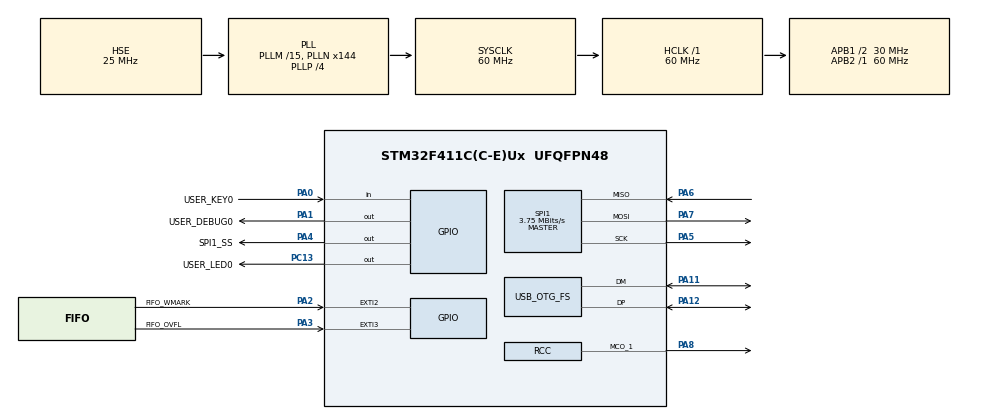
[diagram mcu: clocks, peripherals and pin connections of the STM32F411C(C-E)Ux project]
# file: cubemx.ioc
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Mcu.Family=STM32F4
Mcu.Name=STM32F411C(C-E)Ux
Mcu.Package=UFQFPN48
NVIC.EXTI2_IRQn=true\:0\:0\:false\:false\:true\:true\:true\:true
NVIC.EXTI3_IRQn=true\:0\:0\:false\:false\:true\:true\:true\:true
NVIC.OTG_FS_IRQn=true\:0\:0\:false\:false\:true\:false\:true\:true
NVIC.PriorityGroup=NVIC_PRIORITYGROUP_4
NVIC.TIM3_IRQn=true\:0\:0\:false\:false\:true\:true\:true\:true
PA0-WKUP.GPIO_Label=USER_KEY0
PA0-WKUP.Signal=GPIO_Input
PA1.GPIO_Label=USER_DEBUG0
PA1.GPIO_PuPd=GPIO_PULLDOWN
PA1.Signal=GPIO_Output
PA11.Mode=Device_Only
PA11.Signal=USB_OTG_FS_DM
PA12.Mode=Device_Only
PA12.Signal=USB_OTG_FS_DP
PA13.Mode=Serial_Wire
PA13.Signal=SYS_JTMS-SWDIO
PA14.Mode=Serial_Wire
PA14.Signal=SYS_JTCK-SWCLK
PA2.GPIO_Label=FIFO_WMARK
PA2.GPIO_ModeDefaultEXTI=GPIO_MODE_IT_RISING_FALLING
PA2.GPIO_PuPd=GPIO_PULLDOWN
PA2.Signal=GPXTI2
PA3.GPIO_Label=FIFO_OVFL
PA3.GPIO_ModeDefaultEXTI=GPIO_MODE_IT_RISING_FALLING
PA3.GPIO_PuPd=GPIO_PULLDOWN
PA3.Signal=GPXTI3
PA4.GPIO_Label=SPI1_SS
PA4.GPIO_PuPd=GPIO_NOPULL
PA4.GPIO_Speed=GPIO_SPEED_FREQ_LOW
PA4.PinState=GPIO_PIN_SET
PA4.Signal=GPIO_Output
PA5.GPIO_PuPd=GPIO_NOPULL
PA5.GPIO_Speed=GPIO_SPEED_FREQ_LOW
PA5.Mode=Full_Duplex_Master
PA5.Signal=SPI1_SCK
PA6.GPIO_PuPd=GPIO_NOPULL
PA6.GPIO_Speed=GPIO_SPEED_FREQ_LOW
PA6.Mode=Full_Duplex_Master
PA6.Signal=SPI1_MISO
PA7.GPIO_PuPd=GPIO_NOPULL
PA7.GPIO_Speed=GPIO_SPEED_FREQ_LOW
PA7.Mode=Full_Duplex_Master
PA7.Signal=SPI1_MOSI
PA8.Mode=Clock-out-1
PA8.Signal=RCC_MCO_1
PC13-ANTI_TAMP.GPIO_Label=USER_LED0
PC13-ANTI_TAMP.PinState=GPIO_PIN_SET
PC13-ANTI_TAMP.Signal=GPIO_Output
PC14-OSC32_IN.Mode=LSE-External-Oscillator
PC14-OSC32_IN.Signal=RCC_OSC32_IN
PC15-OSC32_OUT.Mode=LSE-External-Oscillator
PC15-OSC32_OUT.Signal=RCC_OSC32_OUT
PH0\ -\ OSC_IN.Mode=HSE-External-Oscillator
PH0\ -\ OSC_IN.Signal=RCC_OSC_IN
PH1\ -\ OSC_OUT.Mode=HSE-External-Oscillator
PH1\ -\ OSC_OUT.Signal=RCC_OSC_OUT
ProjectManager.HeapSize=0x200
ProjectManager.StackSize=0x400
ProjectManager.TargetToolchain=STM32CubeIDE
RCC.48MHZClocksFreq_Value=48000000
RCC.AHBFreq_Value=60000000
RCC.APB1CLKDivider=RCC_HCLK_DIV2
RCC.APB1Freq_Value=30000000
RCC.APB1TimFreq_Value=60000000
RCC.APB2Freq_Value=60000000
RCC.APB2TimFreq_Value=60000000
RCC.CortexFreq_Value=60000000
RCC.HCLKFreq_Value=60000000
RCC.HSE_VALUE=25000000
RCC.HSI_VALUE=16000000
RCC.PLLM=15
RCC.PLLN=144
RCC.PLLP=RCC_PLLP_DIV4
RCC.PLLQ=5
RCC.RCC_MCO1Source=RCC_MCO1SOURCE_PLLCLK
RCC.RCC_MCODiv1=RCC_MCODIV_5
RCC.RCC_RTC_Clock_SourceVirtual=RCC_RTCCLKSOURCE_LSE
RCC.SYSCLKFreq_VALUE=60000000
RCC.SYSCLKSource=RCC_SYSCLKSOURCE_PLLCLK
RCC.VCOOutputFreq_Value=240000000
SPI1.BaudRatePrescaler=SPI_BAUDRATEPRESCALER_16
SPI1.CLKPhase=SPI_PHASE_2EDGE
SPI1.CLKPolarity=SPI_POLARITY_HIGH
SPI1.CalculateBaudRate=3.75 MBits/s
SPI1.Direction=SPI_DIRECTION_2LINES
SPI1.FirstBit=SPI_FIRSTBIT_MSB
SPI1.Mode=SPI_MODE_MASTER
SPI1.VirtualType=VM_MASTER
TIM3.AutoReloadPreload=TIM_AUTORELOAD_PRELOAD_ENABLE
TIM3.Period=300
TIM3.Prescaler=0
USB_DEVICE.APP_RX_DATA_SIZE=2048
USB_DEVICE.CLASS_NAME_FS=CDC
USB_DEVICE.MANUFACTURER_STRING=3DP Accelerometer
USB_DEVICE.PID_CDC_FS=57626
USB_DEVICE.PRODUCT_STRING_CDC_FS=3dpaxxel
USB_DEVICE.USBD_SELF_POWERED=0
USB_DEVICE.VID=4617
USB_DEVICE.VirtualMode=Cdc
USB_DEVICE.VirtualModeFS=Cdc_FS
USB_OTG_FS.VirtualMode=Device_Only
VP_RTC_VS_RTC_Activate.Mode=RTC_Enabled
VP_TIM3_VS_ClockSourceINT.Mode=Internal
VP_USB_DEVICE_VS_USB_DEVICE_CDC_FS.Mode=CDC_FS
board=custom

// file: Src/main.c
/* USER CODE BEGIN Header */
/**
 ******************************************************************************
 * @file           : main.c
 * @brief          : Main program body
 ******************************************************************************
 * @attention
 *
 * Copyright (c) 2023 STMicroelectronics.
 * All rights reserved.
 *
 * This software is licensed under terms that can be found in the LICENSE file
 * in the root directory of this software component.
 * If no LICENSE file comes with this software, it is provided AS-IS.
 *
 ******************************************************************************
 */
/* USER CODE END Header */
#include "main.h"
#include "gpio.h"
#include "rtc.h"
#include "spi.h"
#include "tim.h"
#include "usb_device.h"

/* USER CODE BEGIN Includes */
#include "fw/controller_impl.h"
/* USER CODE END Includes */

/* USER CODE BEGIN PV */
// extern struct Controller_Handle controllerHandle;
/* USER CODE END PV */

void SystemClock_Config(void);

int main(void)
{

  /* MCU Configuration--------------------------------------------------------*/

  /* Reset of all peripherals, Initializes the Flash interface and the Systick. */
  HAL_Init();

  /* Configure the system clock */
  SystemClock_Config();

  /* Initialize all configured peripherals */
  MX_GPIO_Init();
  MX_RTC_Init();
  MX_SPI1_Init();
  MX_TIM3_Init();
  MX_USB_DEVICE_Init();
  /* USER CODE BEGIN 2 */
  controllerHandle.init();
  /* USER CODE END 2 */

  /* Infinite loop */
  /* USER CODE BEGIN WHILE */
  while (1) {
    controllerHandle.loop();
    /* USER CODE END WHILE */

  }
}

void SystemClock_Config(void)
{
  RCC_OscInitTypeDef RCC_OscInitStruct = {0};
  RCC_ClkInitTypeDef RCC_ClkInitStruct = {0};

  /** Configure the main internal regulator output voltage
  */
  __HAL_RCC_PWR_CLK_ENABLE();
  __HAL_PWR_VOLTAGESCALING_CONFIG(PWR_REGULATOR_VOLTAGE_SCALE1);

  /** Initializes the RCC Oscillators according to the specified parameters
  * in the RCC_OscInitTypeDef structure.
  */
  RCC_OscInitStruct.OscillatorType = RCC_OSCILLATORTYPE_HSE|RCC_OSCILLATORTYPE_LSE;
  RCC_OscInitStruct.HSEState = RCC_HSE_ON;
  RCC_OscInitStruct.LSEState = RCC_LSE_ON;
  RCC_OscInitStruct.PLL.PLLState = RCC_PLL_ON;
  RCC_OscInitStruct.PLL.PLLSource = RCC_PLLSOURCE_HSE;
  RCC_OscInitStruct.PLL.PLLM = 15;
  RCC_OscInitStruct.PLL.PLLN = 144;
  RCC_OscInitStruct.PLL.PLLP = RCC_PLLP_DIV4;
  RCC_OscInitStruct.PLL.PLLQ = 5;
  if (HAL_RCC_OscConfig(&RCC_OscInitStruct) != HAL_OK)
  {
    Error_Handler();
  }

  /** Initializes the CPU, AHB and APB buses clocks
  */
  RCC_ClkInitStruct.ClockType = RCC_CLOCKTYPE_HCLK|RCC_CLOCKTYPE_SYSCLK
                              |RCC_CLOCKTYPE_PCLK1|RCC_CLOCKTYPE_PCLK2;
  RCC_ClkInitStruct.SYSCLKSource = RCC_SYSCLKSOURCE_PLLCLK;
  RCC_ClkInitStruct.AHBCLKDivider = RCC_SYSCLK_DIV1;
  RCC_ClkInitStruct.APB1CLKDivider = RCC_HCLK_DIV2;
  RCC_ClkInitStruct.APB2CLKDivider = RCC_HCLK_DIV1;

  if (HAL_RCC_ClockConfig(&RCC_ClkInitStruct, FLASH_LATENCY_1) != HAL_OK)
  {
    Error_Handler();
  }
  HAL_RCC_MCOConfig(RCC_MCO1, RCC_MCO1SOURCE_PLLCLK, RCC_MCODIV_5);
}

void Error_Handler(void)
{
  /* USER CODE BEGIN Error_Handler_Debug */
  controllerHandle.fault_onErrorHandler();
  /* User can add his own implementation to report the HAL error return state */
  __disable_irq();
  while (1) {
  }
  /* USER CODE END Error_Handler_Debug */
}

#ifdef  USE_FULL_ASSERT
/**
  * @brief  Reports the name of the source file and the source line number
  *         where the assert_param error has occurred.
  * @param  file: pointer to the source file name
  * @param  line: assert_param error line source number
  * @retval None
  */
void assert_failed(uint8_t *file, uint32_t line)
{
  /* USER CODE BEGIN 6 */
  /* User can add his own implementation to report the file name and line
     number, ex: printf("Wrong parameters value: file %s on line %d\r\n", file,
     line) */
  /* USER CODE END 6 */
}
#endif /* USE_FULL_ASSERT */
